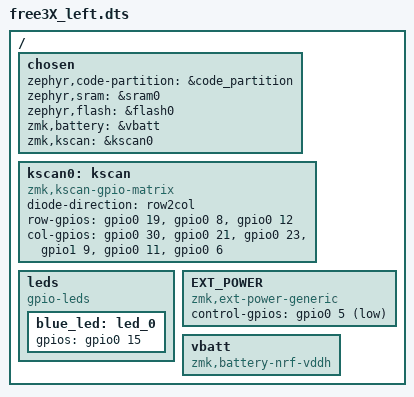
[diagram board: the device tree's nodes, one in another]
/*
 * SPDX-License-Identifier: MIT
 */


#include "free3X.dtsi"


/ {

    chosen {
        zephyr,code-partition = &code_partition;
        zephyr,sram = &sram0;
        zephyr,flash = &flash0;
        zmk,battery = &vbatt;
        zmk,kscan = &kscan0;
    };

    kscan0: kscan {
        compatible = "zmk,kscan-gpio-matrix";

        diode-direction = "row2col";
        row-gpios
            = <&gpio0 19 GPIO_ACTIVE_HIGH>
            , <&gpio0 8 GPIO_ACTIVE_HIGH>
            , <&gpio0 12 GPIO_ACTIVE_HIGH>
            ;
        col-gpios
            = <&gpio0 30 (GPIO_ACTIVE_HIGH | GPIO_PULL_DOWN)>
            , <&gpio0 21 (GPIO_ACTIVE_HIGH | GPIO_PULL_DOWN)>
            , <&gpio0 23 (GPIO_ACTIVE_HIGH | GPIO_PULL_DOWN)>
            , <&gpio1 9 (GPIO_ACTIVE_HIGH | GPIO_PULL_DOWN)>
            , <&gpio0 11 (GPIO_ACTIVE_HIGH | GPIO_PULL_DOWN)>
            , <&gpio0 6 (GPIO_ACTIVE_HIGH | GPIO_PULL_DOWN)>
            ;
    };

    leds {
        compatible = "gpio-leds";
        blue_led: led_0 {
            gpios = <&gpio0 15 GPIO_ACTIVE_HIGH>;
        };
    };

    // Node name must match original "EXT_POWER" label to preserve user settings.
    EXT_POWER {
        compatible = "zmk,ext-power-generic";
        control-gpios = <&gpio0 5 GPIO_ACTIVE_LOW>;
    };

    vbatt: vbatt {
        compatible = "zmk,battery-nrf-vddh";
    };
};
